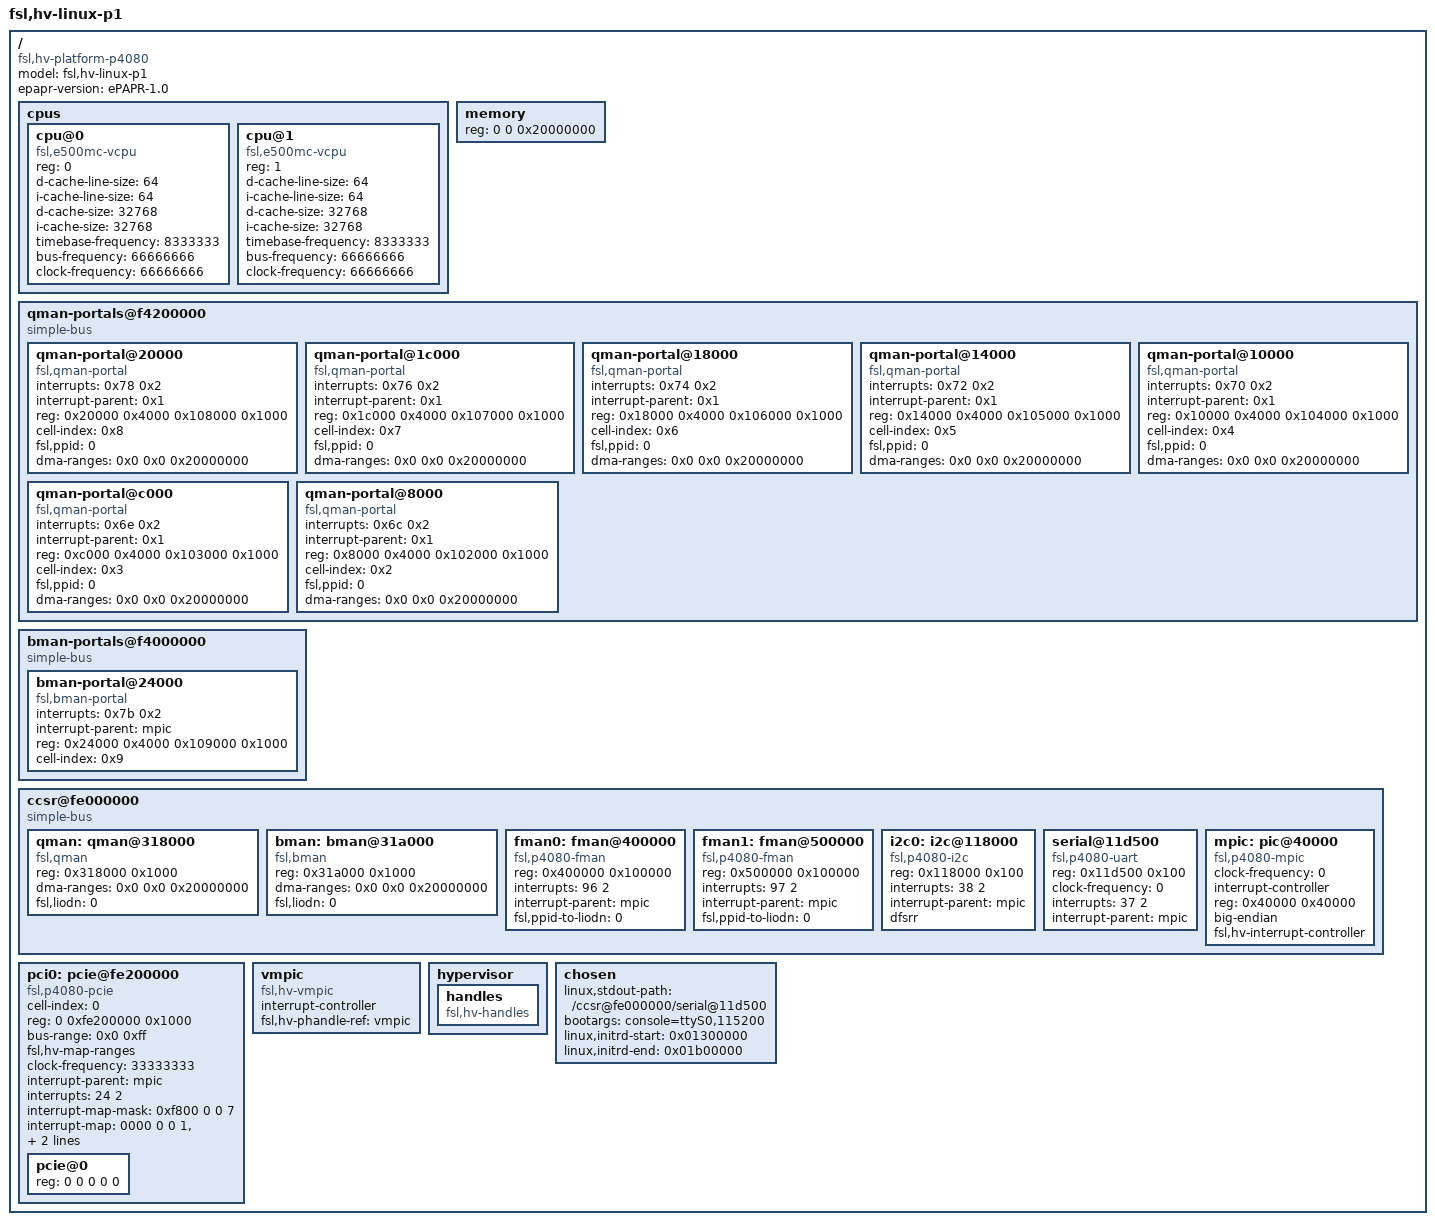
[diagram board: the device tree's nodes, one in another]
/dts-v1/;

/ {
	compatible = "fsl,hv-platform-p4080", "simple-bus";
	model = "fsl,hv-linux-p1";
	epapr-version = "ePAPR-1.0";
	#address-cells = <2>;
	#size-cells = <1>;

	cpus {
		#address-cells = <1>;
		#size-cells = <0>;

		cpu@0 {
			device_type = "cpu";
			compatible = "fsl,e500mc-vcpu";
			reg = <0>;
			d-cache-line-size = <64>;
			i-cache-line-size = <64>;
			d-cache-size = <32768>;
			i-cache-size = <32768>;
			timebase-frequency = <8333333>;
			bus-frequency = <66666666>;
			clock-frequency = <66666666>;
		};

		cpu@1 {
			device_type = "cpu";
			compatible = "fsl,e500mc-vcpu";
			reg = <1>;
			d-cache-line-size = <64>;
			i-cache-line-size = <64>;
			d-cache-size = <32768>;
			i-cache-size = <32768>;
			timebase-frequency = <8333333>;
			bus-frequency = <66666666>;
			clock-frequency = <66666666>;
		};
	};
	
	memory {
		reg = <0 0 0x20000000>;
		device_type = "memory";
	};

	qman-portals@f4200000 {
		#address-cells = <0x1>;
		#size-cells = <0x1>;
		compatible = "simple-bus";
		ranges = <0x0 0x0 0xf4200000 0x200000>;

		qman-portal@20000 {
			interrupts = <0x78 0x2>;
			interrupt-parent = <0x1>;
			compatible = "fsl,qman-portal";
			reg = <0x20000 0x4000 0x108000 0x1000>;
			cell-index = <0x8>;
			fsl,ppid = <0>;
			dma-ranges = <0x0 0x0 0x20000000>;
		};

		qman-portal@1c000 {
			interrupts = <0x76 0x2>;
			interrupt-parent = <0x1>;
			compatible = "fsl,qman-portal";
			reg = <0x1c000 0x4000 0x107000 0x1000>;
			cell-index = <0x7>;
			fsl,ppid = <0>;
			dma-ranges = <0x0 0x0 0x20000000>;
		};

		qman-portal@18000 {
			interrupts = <0x74 0x2>;
			interrupt-parent = <0x1>;
			compatible = "fsl,qman-portal";
			reg = <0x18000 0x4000 0x106000 0x1000>;
			cell-index = <0x6>;
			fsl,ppid = <0>;
			dma-ranges = <0x0 0x0 0x20000000>;
		};

		qman-portal@14000 {
			interrupts = <0x72 0x2>;
			interrupt-parent = <0x1>;
			compatible = "fsl,qman-portal";
			reg = <0x14000 0x4000 0x105000 0x1000>;
			cell-index = <0x5>;
			fsl,ppid = <0>;
			dma-ranges = <0x0 0x0 0x20000000>;
		};

		qman-portal@10000 {
			interrupts = <0x70 0x2>;
			interrupt-parent = <0x1>;
			compatible = "fsl,qman-portal";
			reg = <0x10000 0x4000 0x104000 0x1000>;
			cell-index = <0x4>;
			fsl,ppid = <0>;
			dma-ranges = <0x0 0x0 0x20000000>;
		};

		qman-portal@c000 {
			interrupts = <0x6e 0x2>;
			interrupt-parent = <0x1>;
			compatible = "fsl,qman-portal";
			reg = <0xc000 0x4000 0x103000 0x1000>;
			cell-index = <0x3>;
			fsl,ppid = <0>;
			dma-ranges = <0x0 0x0 0x20000000>;
		};

		qman-portal@8000 {
			interrupts = <0x6c 0x2>;
			interrupt-parent = <0x1>;
			compatible = "fsl,qman-portal";
			reg = <0x8000 0x4000 0x102000 0x1000>;
			cell-index = <0x2>;
			fsl,ppid = <0>;
			dma-ranges = <0x0 0x0 0x20000000>;
		};
	};

	bman-portals@f4000000 {
		#address-cells = <0x1>;
		#size-cells = <0x1>;
		compatible = "simple-bus";
		ranges = <0 0 0xf4000000 0x200000>;

		bman-portal@24000 {
			interrupts = <0x7b 0x2>;
			interrupt-parent = <&mpic>;
			compatible = "fsl,bman-portal";
			reg = <0x24000 0x4000 0x109000 0x1000>;
			cell-index = <0x9>;
		};
	};

	ccsr@fe000000 {
		#address-cells = <1>;
		#size-cells = <1>;
		compatible = "simple-bus";
		device_type = "soc";
		ranges = <0 0 0xfe000000 0x1000000>;

		qman: qman@318000 {
			compatible = "fsl,qman";
			reg = <0x318000 0x1000>;
			dma-ranges = <0x0 0x0 0x20000000>;
			fsl,liodn = <0>;  // set by u-boot
		};

		bman: bman@31a000 {
			compatible = "fsl,bman";
			reg = <0x31a000 0x1000>;
			dma-ranges = <0x0 0x0 0x20000000>;
			fsl,liodn = <0>;  // set by u-boot
		};

		fman0: fman@400000 {
			compatible = "fsl,p4080-fman", "fsl,fman";
			reg = <0x400000 0x100000>;
			interrupts = <96 2>;
			interrupt-parent = <&mpic>;
			fsl,ppid-to-liodn = <0>;
		};

		fman1: fman@500000 {
			compatible = "fsl,p4080-fman", "fsl,fman";
			reg = <0x500000 0x100000>;
			interrupts = <97 2>;
			interrupt-parent = <&mpic>;
			fsl,ppid-to-liodn = <0>;
		};

		i2c0: i2c@118000 {
			device_type = "i2c";
			compatible = "fsl,p4080-i2c",
			             "fsl,i2c", "fsl-i2c";
			reg = <0x118000 0x100>;
			interrupts = <38 2>;
			interrupt-parent = <&mpic>;
			dfsrr;
		};

		serial@11d500 {		// UART2
			device_type = "serial";
			compatible = "fsl,p4080-uart",
				     "fsl,ns16550", "ns16550";
			reg = <0x11d500 0x100>;
			clock-frequency = <0>;
			interrupts = <37 2>;
			interrupt-parent = <&mpic>;
		};

		mpic: pic@40000 {
			clock-frequency = <0>;
			interrupt-controller;
			#address-cells = <0>;
			#interrupt-cells = <2>;
			reg = <0x40000 0x40000>;
			compatible = "fsl,p4080-mpic", "fsl,mpic",
			             "chrp,open-pic";
			device_type = "open-pic";
			big-endian;
			fsl,hv-interrupt-controller;
		};

	};

	pci0: pcie@fe200000 {
		cell-index = <0>;
		compatible = "fsl,p4080-pcie", "fsl,mpc8548-pcie";
		device_type = "pci";
		#interrupt-cells = <1>;
		#size-cells = <2>;
		#address-cells = <3>;
		reg = <0 0xfe200000 0x1000>;
		bus-range = <0x0 0xff>;
		fsl,hv-map-ranges;
		ranges = <0x02000000 0 0x80000000 0 0x80000000 0x0 0x20000000
		          0x01000000 0 0x00000000 0 0xffc00000 0x0 0x00010000>;
		clock-frequency = <33333333>;
		interrupt-parent = <&mpic>;
		interrupts = <24 2>;

		interrupt-map-mask = <0xf800 0 0 7>;
		interrupt-map = <
			/* IDSEL 0x0 */
			0000 0 0 1 &mpic 40 1
			0000 0 0 2 &mpic 1 1
			0000 0 0 3 &mpic 2 1
			0000 0 0 4 &mpic 3 1
		>;

		pcie@0 {
			reg = <0 0 0 0 0>;
			#size-cells = <2>;
			#address-cells = <3>;
			device_type = "pci";
			ranges = <0x02000000 0 80000000
				  0x02000000 0 80000000
				  0 0x20000000

				  0x01000000 0 00000000
				  0x01000000 0 00000000
				  0 0x00010000>;
		};
	};

	vmpic:vmpic {
		compatible = "fsl,hv-vmpic";
		interrupt-controller;
		#interrupt-cells = <2>;
		fsl,hv-phandle-ref = <&vmpic>;
	};

	hypervisor {
		handles {
			#address-cells = <1>;
			#size-cells = <0>;
			compatible = "fsl,hv-handles";
		};
	};

	chosen {
		linux,stdout-path = "/ccsr@fe000000/serial@11d500";
		bootargs = "console=ttyS0,115200";
		linux,initrd-start = <0x01300000>;
		linux,initrd-end = <0x01b00000>;
	};
};
